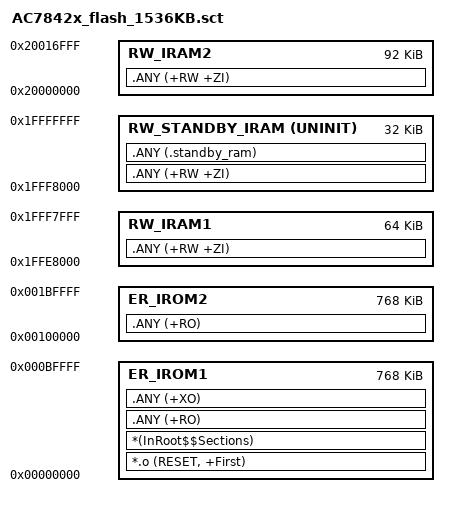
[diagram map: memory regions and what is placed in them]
; *************************************************************
; *** Scatter-Loading Description File generated by uVision ***
; *************************************************************

LR_IROM1 0x00000000 0x000C0000  {    ; load region size_region
  ER_IROM1 0x00000000 0x000C0000  {  ; load address = execution address
   *.o (RESET, +First)
   *(InRoot$$Sections)
   .ANY (+RO)
   .ANY (+XO)
  }

  RW_IRAM1 0x1FFE8000 0x00018000-0x8000  {  ; SRAM_L
   .ANY (+RW +ZI)
  }

  RW_STANDBY_IRAM 0x1FFF8000 UNINIT 0x8000  {  ; standby power mode retention RAM
   .ANY (+RW +ZI)
   .ANY (.standby_ram)
  }

  RW_IRAM2 0x20000000 0x00017000  {  ; SRAM_U
   .ANY (+RW +ZI)
  }
}

LR_IROM2 0x00100000 0x000C0000  {    ; load region size_region
  ER_IROM2 0x00100000 0x000C0000  {  ; load address = execution address
   .ANY (+RO)
  }
}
